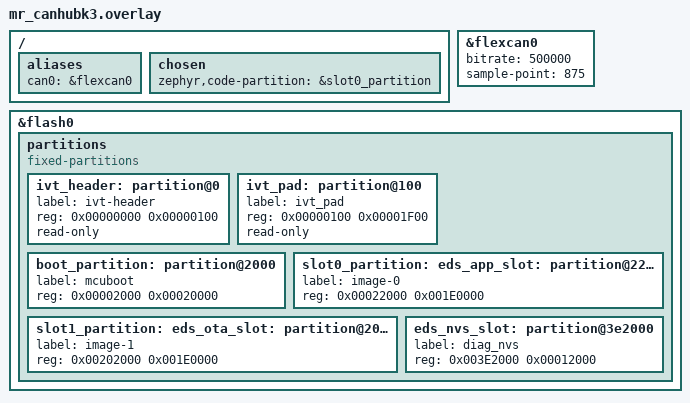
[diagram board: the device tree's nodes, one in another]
/*
 * =============================================================================
 * Xaloqi EDS
 * boards/mr_canhubk3/mr_canhubk3.overlay
 *
 * Device Tree overlay for the NXP MR-CANHUBK3 board (NXP S32K344, Cortex-M7).
 *
 * TARGET SOC : NXP S32K344 — Cortex-M7 @ 160 MHz, 4 MB program flash,
 *              320 KB SRAM, up to 6× FlexCAN-FD instances.
 * BOARD      : NXP MR-CANHUBK3 evaluation module.
 *              The same FlexCAN0 peripheral and pinout applies to S32K312
 *              and S32K396 variants with minor clock-tree Kconfig adjustments.
 *
 * PURPOSE: Configure FlexCAN0 as the EDS diagnostic CAN channel at 500 kbit/s
 *          and define the NVS / OTA flash partition layout.
 *
 * HARDWARE SETUP:
 *   MR-CANHUBK3 → NXP TJA1443 CAN transceiver (on-board, CAN0 connector)
 *   PTA6 (CAN0_RX) → TJA1443 RXD  (defined in mr_canhubk3-pinctrl.dtsi)
 *   PTA7 (CAN0_TX) → TJA1443 TXD  (defined in mr_canhubk3-pinctrl.dtsi)
 *   The TJA1443 on the MR-CANHUBK3 is a GPIO-controlled CAN transceiver.
 *   GPIO PC8 (enable) and PC5 (standby) are managed by the board DTSI.
 *   CANH/CANL connect to the board's D-Sub9 CAN0 connector.
 *
 *   Debug UART: LPUART2 (on-board USB-to-serial, 115200 baud).
 *   No USB-UART adapter needed.
 *
 * CAN BUS PARAMETERS:
 *   Bus speed : 500 kbit/s  (ISO 15765-4 §4.2 for 11-bit CAN IDs)
 *   Sample point: 87.5%    (CiA 601 / CANopen automotive convention)
 *   Mode: Classic CAN 2.0B (CAN FD mode is available — see Notes)
 *
 * PINMUX:
 *   FlexCAN0 pinmux (PTA6/PTA7) is defined in mr_canhubk3-pinctrl.dtsi
 *   (upstream Zephyr). The board DTSI references these pinctrl groups on
 *   &flexcan0. No additional pinctrl definitions are needed in this overlay.
 *
 * FLASH LAYOUT (EDS#627):
 *   This follows Zephyr's own MCUboot variant of this board,
 *   boards/nxp/mr_canhubk3/mr_canhubk3_s32k344_mcuboot.dts (Zephyr v4.4.0 and
 *   later), offset for offset and with the same node labels. EDS adds one
 *   partition, diag_nvs, in the flash that layout leaves free after image-1.
 *   The same map serves a plain build (this board, no bootloader) and an
 *   MCUboot build (mr_canhubk3/s32k344/mcuboot), so DTC storage never moves
 *   when a bench switches between the two.
 *
 *   S32K344 program flash: 4048 KiB (the board's flash0 size), 8 KiB
 *   sectors, mapped at 0x00400000. Offsets are relative to that base.
 *
 *   Offset     Size       Node label           Purpose
 *   ---------  ---------  -------------------  ----------------------------------
 *   0x000000   256 B      ivt_header           S32K3 boot header (IVT). The boot
 *                                              ROM looks for it at 0x00400000.
 *   0x000100   7936 B     ivt_pad              Rest of the first sector.
 *   0x002000   128 KiB    boot_partition       MCUboot. Unused (left erased) in
 *                                              a plain build.
 *   0x022000   1920 KiB   slot0_partition      image-0, zephyr,code-partition.
 *   0x202000   1920 KiB   slot1_partition      image-1, the OTA / MCUboot
 *                                              secondary slot
 *                                              (platform/zephyr/zephyr_flash_ops.c).
 *   0x3E2000   72 KiB     eds_nvs_slot         diag_nvs: Zephyr NVS, 9 x 8 KiB.
 *   ---------------------------------------------------------------------------
 *   0x2000 + 0x20000 + 0x1E0000 + 0x1E0000 + 0x12000 = 0x3F4000 = 4048 KiB
 *
 *   The boot header needs no external tool. Zephyr's
 *   soc/nxp/s32/s32k3/soc.c emits the IVT into the ivt_header partition
 *   (section .ivt_header) with the Cortex-M7_0 start address set to the
 *   image's own vector table. A plain build therefore starts at 0x00422000;
 *   in an MCUboot build, MCUboot's image carries the IVT and starts at
 *   0x00402000. soc/nxp/s32/s32k3/Kconfig derives IVT_HEADER_OFFSET/SIZE
 *   from the ivt_header label, so that label must stay.
 *
 *   Zephyr v4.4.0 and later: the internal-flash driver (flash_mcux_c40.c,
 *   on by default) write-protects the ivt_header, ivt_pad and boot_partition
 *   windows by these labels and runs erase/program from SRAM. Zephyr
 *   v3.7.0 (EDS's west.yml pin) has no driver for this flash: the image
 *   builds and carries its boot header, but NVS and OTA writes have no
 *   device there (see examples/basic_ecu/src/main.c).
 *
 * SAFETY: This overlay is a starting point. OEM integration must:
 *   [ ] Verify PTA6/PTA7 pinout against actual S32K344 schematic variant
 *   [ ] Validate 500 kbit/s sample point against network analyser
 *   [ ] Enable CAN termination resistor (120 Ω) on bus endpoints
 *   [ ] Qualify FlexCAN0 against ISO 11898-1 electrical requirements
 *
 * NOTES:
 *   CAN FD: Set CONFIG_CAN_FD_MODE=y and update sample-point + data-sample-point
 *   in this overlay when CAN FD payloads (>8 bytes) are required.
 *   S32K312 / S32K396 variants: reuse this overlay with minor adjustments to
 *   clock sources (NXP_S32_FLEXCANA_CLK) if the SoC clock tree differs.
 * =============================================================================
 */

/* ── CAN alias: can0 → flexcan0 ──────────────────────────────────────────────
 *
 * main.c uses DEVICE_DT_GET(DT_ALIAS(can0)) — this alias maps that to FlexCAN0.
 * mr_canhubk3_common.dtsi sets zephyr,canbus = &flexcan0 in the chosen node.
 *
 * WATCHDOG: the board DTS sets watchdog0, and it differs by Zephyr version:
 *   v3.7.0 points it at &fs26_wdt (the FS26 safety SBC's watchdog, over SPI);
 *   v4.4.0 and later point it at &swt0 (the S32K344's internal SWT).
 * We do not override watchdog0 here; the board's alias is used as it is.
 * ─────────────────────────────────────────────────────────────────────────── */
/ {
	aliases {
		can0 = &flexcan0;
	};

	chosen {
		zephyr,code-partition = &slot0_partition;
	};
};

/* ── FlexCAN0 timing ──────────────────────────────────────────────────────────
 *
 * mr_canhubk3_common.dtsi enables flexcan0 with PTA6/PTA7 pinctrl and the
 * on-board TJA1443 transceiver. We add the bitrate and the sample point.
 *
 * Sample point = 87.5% — standard automotive ECU configuration (CiA 601).
 * The FlexCAN driver computes bit-timing registers from sample-point at init.
 * ─────────────────────────────────────────────────────────────────────────── */
&flexcan0 {
	/* [EDS#631] Without bitrate the controller runs at CONFIG_CAN_DEFAULT_BITRATE
	 * (Zephyr default 125000), not the documented 500 kbit/s (as #309 on the NUCLEO). */
	bitrate      = <500000>;
	sample-point = <875>;
};

/* ── Flash partition table ────────────────────────────────────────────────────
 *
 * The layout in the header above. The board's own partitions node (ivt-header
 * plus one code-partition) is replaced, because EDS needs image-1 and
 * diag_nvs. The nodes and labels up to slot1_partition are those of Zephyr's
 * mr_canhubk3_s32k344_mcuboot.dts; the eds_* labels are the names EDS code
 * and the other EDS board overlays use.
 * ─────────────────────────────────────────────────────────────────────────── */
&flash0 {
	/delete-node/ partitions;

	partitions {
		compatible = "fixed-partitions";
		#address-cells = <1>;
		#size-cells = <1>;

		ivt_header: partition@0 {
			label = "ivt-header";
			reg = <0x00000000 0x00000100>;
			read-only;
		};

		ivt_pad: partition@100 {
			label = "ivt_pad";
			reg = <0x00000100 0x00001F00>;
			read-only;
		};

		boot_partition: partition@2000 {
			label = "mcuboot";
			reg = <0x00002000 0x00020000>; /* 128 KiB */
		};

		slot0_partition: eds_app_slot: partition@22000 {
			label = "image-0";
			reg = <0x00022000 0x001E0000>; /* 1920 KiB */
		};

		slot1_partition: eds_ota_slot: image_1: partition@202000 {
			label = "image-1";
			reg = <0x00202000 0x001E0000>; /* 1920 KiB */
		};

		eds_nvs_slot: partition@3e2000 {
			label = "diag_nvs";
			reg = <0x003E2000 0x00012000>; /* 72 KiB = 9 x 8 KiB sectors */
		};
	};
};
